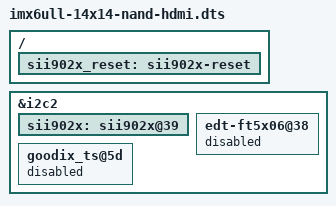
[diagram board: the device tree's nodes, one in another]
#include "imx6ull-14x14-evk-gpmi-weim.dts"

/ {
       sii902x_reset: sii902x-reset {
                status = "okay";
        };
};

&i2c2 {
	sii902x: sii902x@39{
		status = "okay";
	};

        edt-ft5x06@38 {
                status = "disabled";
        };

        goodix_ts@5d {
                status = "disabled";
        };
};
